# R7FA6M5BH register map
Vendor: Renesas Electronics Corporation; Series: RA6; File version: 1.20.01
CPU: CM33 r0p4, little endian, MPU, FPU, VTOR, 4 interrupt priority bits, 96 interrupts
Registers are 32-bit, read-write, reset 0x0 unless marked. A register's access mark holds for its fields unless they carry their own. Offsets are from the block's base; [hi:lo] are bit positions; {n}, {i} and the like mark numbered series; 'fields as' and 'values as' point back to an identical list; <NAME> marks a mode.

## SYSC — System Control
Base 0x4001E000
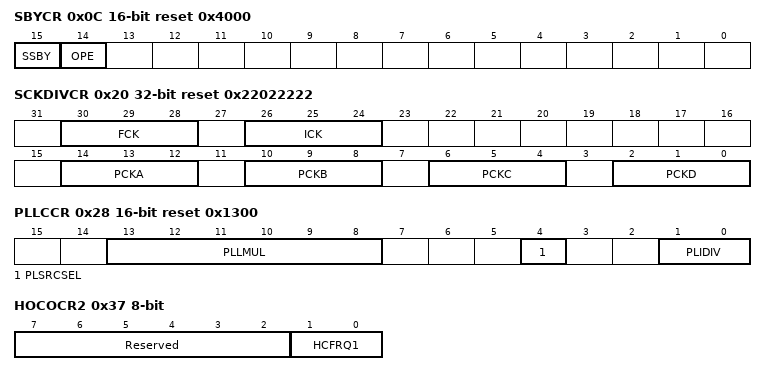
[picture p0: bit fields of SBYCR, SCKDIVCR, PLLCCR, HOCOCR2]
0x0C SBYCR 16-bit reset 0x4000 — Standby Control Register
  [15] SSBY — Software Standby Mode Select
    0=Sleep mode; 1=Software Standby mode
  [14] OPE — Output Port Enable
    0=In Software Standby mode or Deep Software Standby mode, set the address bus and other bus control signal to the high-impedance state. In snooze mode, the status of the address bus and bus control signals are same as before entering Software Standby mode.; 1=In Software Standby mode or Deep Software Standby mode, address bus and other bus control signal retain the output state
0x20 SCKDIVCR reset 0x22022222 — System Clock Division Control Register
  [all] fields
    0=x 1/1; 1=x 1/2; 2=x 1/4; 3=x 1/8; 4=x 1/16; 5=x 1/32; 6=x 1/64; other=Others (Setting prohibited.)
  [30:28] FCK — FlashIF Clock (FCLK) Select
  [26:24] ICK — System Clock (ICLK) Select
  [14:12] PCKA — Peripheral Module Clock A (PCLKA) Select
  [10:8] PCKB — Peripheral Module Clock B (PCLKB) Select
  [6:4] PCKC — Peripheral Module Clock C (PCLKC) Select
  [2:0] PCKD — Peripheral Module Clock D (PCLKD) Select
0x26 SCKSCR 8-bit reset 0x1 — System Clock Source Control Register
  [2:0] CKSEL — Clock Source Select
    0=HOCO; 1=MOCO; 2=LOCO; 3=Main clock oscillator (MOSC); 4=Sub-clock oscillator (SOSC); 5=PLL; 6=Setting prohibited; 7=Setting prohibited
0x28 PLLCCR 16-bit reset 0x1300 — PLL Clock Control Register
  [13:8] PLLMUL range 0x13..0x3B — PLL Frequency Multiplication Factor Select
  [4] PLSRCSEL — PLL Clock Source Select
    0=Main clock oscillator; 1=HOCO
  [1:0] PLIDIV — PLL Input Frequency Division Ratio Select
    0=/1; 1=/2; 2=/3; other=Others (Setting prohibited.)
0x2A PLLCR 8-bit reset 0x1 — PLL Control Register
  [0] PLLSTP — PLL Stop Control
    0=PLL is operating; 1=PLL is stopped
0x30 BCKCR 8-bit — External Bus Clock Control Register
  [0] BCLKDIV — BCLK Pin Output Select
    0=BCLK; 1=BCLK ∕ 2
0x32 MOSCCR 8-bit reset 0x1 — Main Clock Oscillator Control Register
  [0] MOSTP — Main Clock Oscillator Stop
    0=Operate the main clock oscillator; 1=Stop the main clock oscillator
0x36 HOCOCR 8-bit (reset mask 0xFE) — High-Speed On-Chip Oscillator Control Register
  [0] HCSTP — HOCO Stop
    0=Operate the HOCO clock; 1=Stop the HOCO clock
0x37 HOCOCR2 8-bit (reset mask 0xFC) — High-Speed On-Chip Oscillator Control Register 2
  [7:2] Reserved — These bits are read as 000000. The write value should be 000000.
  [1:0] HCFRQ1 — HOCO Frequency Setting 0
    0=16 MHz; 1=18 MHz; 2=20 MHz; other=others (Setting prohibited)
0x38 MOCOCR 8-bit — Middle-Speed On-Chip Oscillator Control Register
  [0] MCSTP — MOCO Stop
    0=MOCO clock is operating; 1=MOCO clock is stopped
0x39 FLLCR1 8-bit — FLL Control Register1
  [0] FLLEN — FLL Enable
    0=FLL function is disabled; 1=FLL function is enabled
0x3A FLLCR2 16-bit — FLL Control Register2
  [10:0] FLLCNTL — FLL Multiplication Control
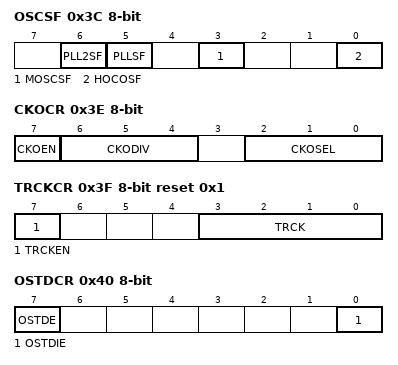
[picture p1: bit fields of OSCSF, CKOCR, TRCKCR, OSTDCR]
0x3C OSCSF 8-bit ro (reset mask 0xFE) — Oscillation Stabilization Flag Register
  [6] PLL2SF — PLL2 Clock Oscillation Stabilization Flag
    0=The PLL2 clock is stopped, or oscillation of the PLL2 clock is not stable yet; 1=The PLL2 clock is stable
  [5] PLLSF — PLL Clock Oscillation Stabilization Flag
    0=The PLL clock is stopped, or oscillation of the PLL clock is not stable yet; 1=The PLL clock is stable, so is available for use as the system clock
  [3] MOSCSF — Main Clock Oscillation Stabilization Flag
    0=The main clock oscillator is stopped (MOSTP = 1) or is not yet stable; 1=The main clock oscillator is stable, so is available for use as the system clock
  [0] HOCOSF — HOCO Clock Oscillation Stabilization Flag
    0=The HOCO clock is stopped or is not yet stable; 1=The HOCO clock is stable, so is available for use as the system clock
0x3E CKOCR 8-bit — Clock Out Control Register
  [7] CKOEN — Clock Out Enable
    0=Disable clock out; 1=Enable clock out
  [6:4] CKODIV — Clock Output Frequency Division Ratio
    0=x 1/1; 1=x 1/2; 2=x 1/4; 3=x 1/8; 4=x 1/16; 5=x 1/32; 6=x 1/64; 7=x 1/128
  [2:0] CKOSEL — Clock Out Source Select
    0=HOCO (value after reset); 1=MOCO; 2=LOCO; 3=MOSC; 4=SOSC; 5=Setting prohibited; other=Others (Setting prohibited)
0x3F TRCKCR 8-bit reset 0x1 — Trace Clock Control Register
  [7] TRCKEN — Trace Clock operating Enable
    0=Stop; 1=Operation enable
  [3:0] TRCK — Trace Clock operating frequency select
    0=/1; 1=/2 (value after reset); 2=/4; other=Others (Setting prohibited)
0x40 OSTDCR 8-bit — Oscillation Stop Detection Control Register
  [7] OSTDE — Oscillation Stop Detection Function Enable
    0=Disable oscillation stop detection function; 1=Enable oscillation stop detection function
  [0] OSTDIE — Oscillation Stop Detection Interrupt Enable
    0=Disable oscillation stop detection interrupt (do not notify the POEG); 1=Enable oscillation stop detection interrupt (notify the POEG)
0x41 OSTDSR 8-bit — Oscillation Stop Detection Status Register
  [0] OSTDF — Oscillation Stop Detection Flag
    0=Main clock oscillation stop not detected; 1=Main clock oscillation stop detected
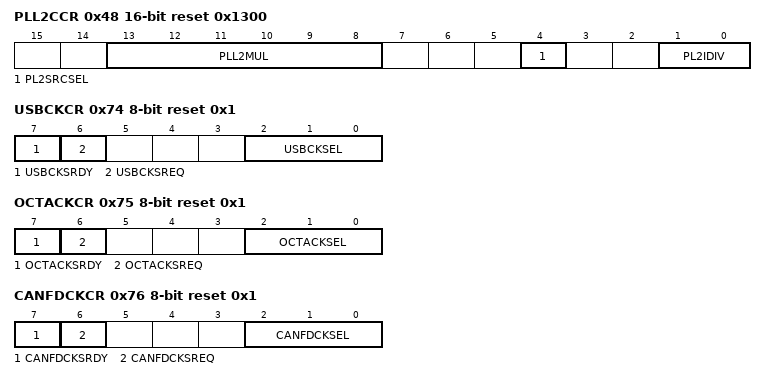
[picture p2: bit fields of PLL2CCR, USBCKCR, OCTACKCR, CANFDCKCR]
0x48 PLL2CCR 16-bit reset 0x1300 — PLL2 Clock Control Register
  [13:8] PLL2MUL — PLL2 Frequency Multiplication Factor Select
  [4] PL2SRCSEL — PLL2 Clock Source Select
    0=Main clock oscillator; 1=HOCO
  [1:0] PL2IDIV — PLL2 Input Frequency Division Ratio Select
    0=∕ 1 (value after reset); 1=∕ 2; 2=∕ 3; other=Others (Setting prohibited.)
0x4A PLL2CR 8-bit reset 0x1 — PLL2 Control Register
  [0] PLL2STP — PLL2 Stop Control
    0=PLL2 is operating; 1=PLL2 is stopped
0x52 EBCKOCR 8-bit — External Bus Clock Output Control Register
  [0] EBCKOEN — EBCLK Pin Output Control
    0=EBCLK pin output is disabled (fixed high); 1=EBCLK pin output is enabled
0x61 MOCOUTCR 8-bit — MOCO User Trimming Control Register
  [7:0] MOCOUTRM — MOCO User Trimming
0x62 HOCOUTCR 8-bit — HOCO User Trimming Control Register
  [7:0] HOCOUTRM — HOCO User Trimming
0x6C USBCKDIVCR 8-bit — USB Clock Division Control Register
  [2:0] USBCKDIV — USB Clock (USBCLK) Division Select
    2=∕ 4; 5=∕ 3; 6=∕ 5; other=Others (Setting prohibited.)
0x6D OCTACKDIVCR 8-bit — Octal-SPI Clock Division Control Register
  [2:0] OCTACKDIV — Octal-SPI Clock (OCTACLK) Division Select
    0=∕ 1 (value after reset); 1=∕ 2; 2=∕ 4; 3=∕ 6; 4=∕ 8; other=Others (Setting prohibited.)
0x6E CANFDCKDIVCR 8-bit — CANFD Clock Division Control Register
  [2:0] CANFDCKDIV — CANFD clock (CANFDCLK) Division Select
    0=/1 (value after reset) /2 /4 /6 /3 /5
0x6F USB60CKDIVCR 8-bit — USB60 Clock Division Control Register
  [2:0] USB60CKDIV — USB clock (USB60CLK) Division Select
    0=/1 (value after reset); 1=/2; 2=/4; 3=/6; 4=/8; 5=/3; 6=/5; other=Others (Setting prohibited)
0x70 CECCKDIVCR 8-bit reset 0x1 — CEC Clock Division Control Register
  [2:0] CECCKDIV — CEC clock (CECCLK) Division Select
    values as USB60CKDIVCR.USB60CKDIV
0x74 USBCKCR 8-bit reset 0x1 — USB Clock Control Register
  [7] USBCKSRDY ro — USB Clock (USBCLK) Switching Ready state flag
    0=Impossible to Switch; 1=Possible to Switch
  [6] USBCKSREQ — USB Clock (USBCLK) Switching Request
    0=No request; 1=Request switching
  [2:0] USBCKSEL — USB Clock (USBCLK) Source Select
    5=PLL; 6=PLL2; other=Others (Setting prohibited.)
0x75 OCTACKCR 8-bit reset 0x1 — Octal-SPI Clock Control Register
  [7] OCTACKSRDY ro — Octal-SPI Clock (OCTACLK) Switching Ready state flag
    0=Switching not possible; 1=Switching possible
  [6] OCTACKSREQ — Octal-SPI Clock (OCTACLK) Switching Request
    0=No request; 1=Request switching
  [2:0] OCTACKSEL — Octal-SPI Clock (OCTACLK) Source Select
    0=HOCO; 1=MOCO (value after reset); 2=LOCO; 3=Main clock oscillator; 4=Sub-clock oscillator; 5=PLL; 6=PLL2; other=Others (Setting prohibited.)
0x76 CANFDCKCR 8-bit reset 0x1 — CANFD Clock Control Register
  [7] CANFDCKSRDY ro — CANFD clock (CANFDCLK) Switching Ready state flag
    0=Impossible to Switch; 1=Possible to Switch
  [6] CANFDCKSREQ — CANFD clock (CANFDCLK) Switching Request
    0=No request; 1=Request switching
  [2:0] CANFDCKSEL — CANFD clock (CANFDCLK) Source Select
    5=PLL; 6=PLL2; other=Others (Setting prohibited)
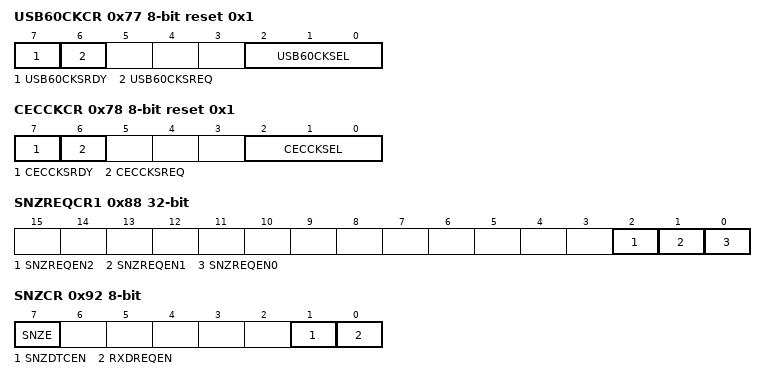
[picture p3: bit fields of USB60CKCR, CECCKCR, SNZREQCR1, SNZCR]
0x77 USB60CKCR 8-bit reset 0x1 — USB60 Clock Control Register
  [7] USB60CKSRDY ro — USB clock (USB60CLK) Switching Ready state flag
    0=Impossible to Switch; 1=Possible to Switch
  [6] USB60CKSREQ — USB clock (USB60CLK) Switching Request
    0=No request; 1=Request switching
  [2:0] USB60CKSEL — USB clock (USB60CLK) Source Select
    5=PLL; 6=PLL2; other=Others (Setting prohibited)
0x78 CECCKCR 8-bit reset 0x1 — CEC Clock Control Register
  [7] CECCKSRDY ro — CEC clock (CECCLK) Switching Ready state flag
    0=Impossible to Switch; 1=Possible to Switch
  [6] CECCKSREQ — CEC clock (CECCLK) Switching Request
    0=No request; 1=Request switching
  [2:0] CECCKSEL — CEC clock (CECCLK) Source Select
    3=Main clock oscillator; 4=Sub-clock oscillator; other=Others (Setting prohibited)
0x88 SNZREQCR1 — Snooze Request Control Register 1
  [all] fields
    0=Disable the snooze request; 1=Enable the snooze request
  [2] SNZREQEN2 — Enable AGT3 compare match B snooze request
  [1] SNZREQEN1 — Enable AGT3 compare match A snooze request
  [0] SNZREQEN0 — Enable AGT3 underflow snooze request
0x92 SNZCR 8-bit — Snooze Control Register
  [7] SNZE — Snooze mode Enable
    0=Disable Snooze mode; 1=Enable Snooze mode
  [1] SNZDTCEN — DTC Enable in Snooze mode
    0=Disable DTC operation; 1=Enable DTC operation
  [0] RXDREQEN — RXD0 Snooze Request Enable
    0=Ignore RXD0 falling edge in Software Standby mode; 1=Detect RXD0 falling edge in Software Standby mode
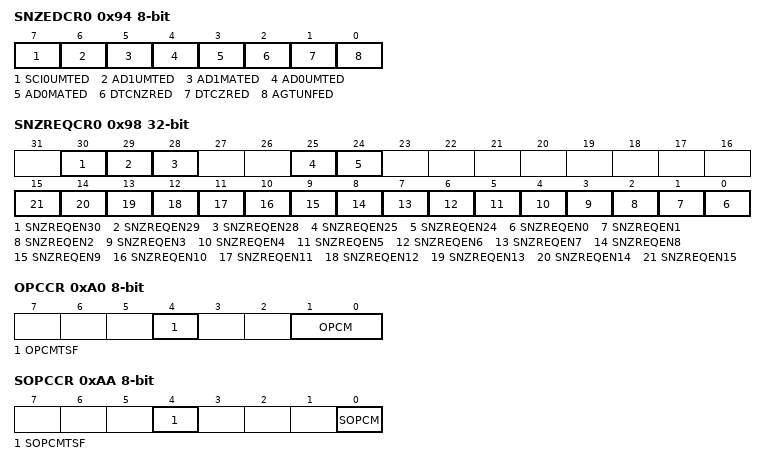
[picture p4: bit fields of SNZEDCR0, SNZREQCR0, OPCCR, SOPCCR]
0x94 SNZEDCR0 8-bit — Snooze End Control Register 0
  [all] fields
    0=Disable the snooze end request; 1=Enable the snooze end request
  [7] SCI0UMTED — SCI0 Address Mismatch Snooze End Enable
  [6] AD1UMTED — ADC121 Compare Mismatch Snooze End Enable
  [5] AD1MATED — ADC121 Compare Match Snooze End Enable
  [4] AD0UMTED — ADC120 Compare Mismatch Snooze End Enable
  [3] AD0MATED — ADC120 Compare Match Snooze End Enable
  [2] DTCNZRED — Not Last DTC Transmission Completion Snooze End Enable
  [1] DTCZRED — Last DTC Transmission Completion Snooze End Enable
  [0] AGTUNFED — AGT1 Underflow Snooze End Enable
0x95 SNZEDCR1 8-bit — Snooze End Control Register 1
  [0] AGT3UNFED — AGT3 underflow Snooze End Enable
    0=Disable the Snooze End request; 1=Enable the Snooze End request
0x98 SNZREQCR0 — Snooze Request Control Register 0
  [all] fields
    0=Disable the snooze request; 1=Enable the snooze request
  [30] SNZREQEN30 — Enable AGT1 compare match B snooze request
  [29] SNZREQEN29 — Enable AGT1 compare match A snooze request
  [28] SNZREQEN28 — Enable AGT1 underflow snooze request
  [25] SNZREQEN25 — Enable RTC period snooze request
  [24] SNZREQEN24 — Enable RTC alarm snooze request
  [n] SNZREQEN{n} (n=0..15) — Enable IRQ{n} pin snooze request
0xA0 OPCCR 8-bit — Operating Power Control Register
  [4] OPCMTSF ro — Operating Power Control Mode Transition Status Flag
    0=Transition completed; 1=During transition
  [1:0] OPCM — Operating Power Control Mode Select
    0=High-speed mode; 1=Setting prohibited; 2=Setting prohibited; 3=Low-speed mode
0xA2 MOSCWTCR 8-bit reset 0x5 — Main Clock Oscillator Wait Control Register
  [3:0] MSTS — Main Clock Oscillator Wait Time Setting
    0=Wait time = 3 cycles (11.4 us); 1=Wait time = 35 cycles (133.5 us); 2=Wait time = 67 cycles (255.6 us); 3=Wait time = 131 cycles (499.7 us); 4=Wait time = 259 cycles (988.0 us); 5=Wait time = 547 cycles (2086.6 us); 6=Wait time = 1059 cycles (4039.8 us); 7=Wait time = 2147 cycles (8190.2 us); 8=Wait time = 4291 cycles (16368.9 us); 9=Wait time = 8163 cycles (31139.4 us); other=Others (Setting prohibited)
0xAA SOPCCR 8-bit — Sub Operating Power Control Register
  [4] SOPCMTSF ro — Operating Power Control Mode Transition Status Flag
    0=Transition completed; 1=During transition
  [0] SOPCM — Sub Operating Power Control Mode Select
    0=Other than Subosc-speed mode; 1=Subosc-speed mode
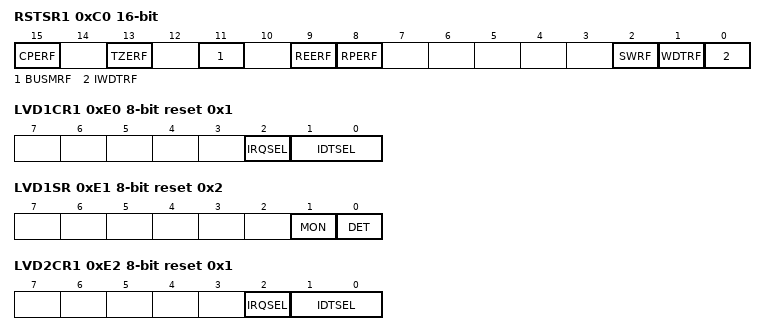
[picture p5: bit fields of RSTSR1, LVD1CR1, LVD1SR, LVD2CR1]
0xC0 RSTSR1 16-bit (reset mask 0x54F8) — Reset Status Register 1
  [15] CPERF — Cache Parity Error Reset Detect Flag
    0=Cache Parity error reset not detected; 1=Cache Parity error reset detected
  [13] TZERF — TrustZone Error Reset Detect Flag
    0=TrustZone error reset not detected; 1=TrustZone error reset detected
  [11] BUSMRF — Bus Master MPU Error Reset Detect Flag
    0=Bus master MPU error reset not detected; 1=Bus master MPU error reset detected
  [9] REERF — SRAM ECC Error Reset Detect Flag
    0=SRAM ECC error reset not detected; 1=SRAM ECC error reset detected
  [8] RPERF — SRAM Parity Error Reset Detect Flag
    0=SRAM parity error reset not detected; 1=SRAM parity error reset detected
  [2] SWRF — Software Reset Detect Flag
    0=Software reset not detected; 1=Software reset detected
  [1] WDTRF — Watchdog Timer Reset Detect Flag
    0=Watchdog timer reset not detected; 1=Watchdog timer reset detected
  [0] IWDTRF — Independent Watchdog Timer Reset Detect Flag
    0=Independent watchdog timer reset not detected; 1=Independent watchdog timer reset detected
0xE0 LVD1CR1 8-bit reset 0x1 — Voltage Monitor 1 Circuit Control Register
  [2] IRQSEL — Voltage Monitor 1 Interrupt Type Select
    0=Non-maskable interrupt; 1=Maskable interrupt
  [1:0] IDTSEL — Voltage Monitor 1 Interrupt Generation Condition Select
    0=When VCC >= Vdet1 (rise) is detected; 1=When VCC < Vdet1 (fall) is detected; 2=When fall and rise are detected; 3=Settings prohibited
0xE1 LVD1SR 8-bit reset 0x2 — Voltage Monitor 1 Circuit Status Register
  [1] MON ro — Voltage Monitor 1 Signal Monitor Flag
    0=VCC < Vdet1; 1=VCC >= Vdet1 or MON is disabled
  [0] DET — Voltage Monitor 1 Voltage Variation Detection Flag
    0=Not detected; 1=Vdet1 crossing is detected
0xE2 LVD2CR1 8-bit reset 0x1 — Voltage Monitor 2 Circuit Control Register 1
  [2] IRQSEL — Voltage Monitor 2 Interrupt Type Select
    0=Non-maskable interrupt; 1=Maskable interrupt
  [1:0] IDTSEL — Voltage Monitor 2 Interrupt Generation Condition Select
    0=When VCC>= Vdet2 (rise) is detected; 1=When VCC < Vdet2 (fall) is detected; 2=When fall and rise are detected; 3=Settings prohibited
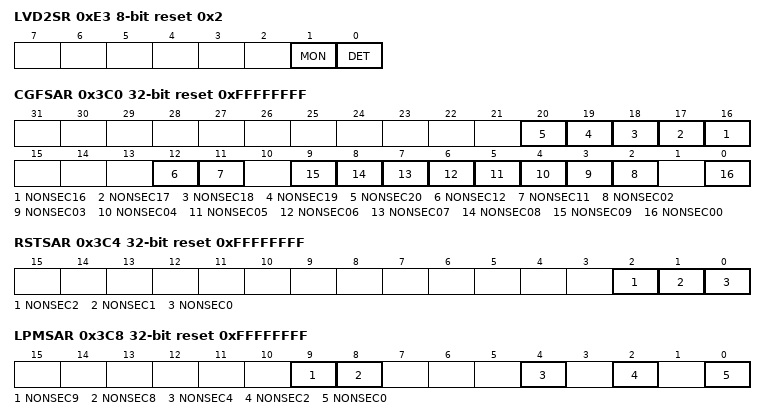
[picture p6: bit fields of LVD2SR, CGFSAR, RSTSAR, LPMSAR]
0xE3 LVD2SR 8-bit reset 0x2 — Voltage Monitor 2 Circuit Status Register
  [1] MON ro — Voltage Monitor 2 Signal Monitor Flag
    0=VCC < Vdet2; 1=VCC>= Vdet2 or MON is disabled
  [0] DET — Voltage Monitor 2 Voltage Variation Detection Flag
    0=Not detected; 1=Vdet2 crossing is detected
0x3C0 CGFSAR reset 0xFFFFFFFF — Clock Generation Function Security Attribute Register
  [all] fields
    0=Secure; 1=Non Secure
  [n] NONSEC{n} (n=16..20) — Non Secure Attribute bit {n}
  [12] NONSEC12 — Non Secure Attribute bit 12
  [11] NONSEC11 — Non Secure Attribute bit 11
  [n] NONSEC{n:02} (n=2..9) — Non Secure Attribute bit {n:02}
  [0] NONSEC00 — Non Secure Attribute bit 00
0x3C4 RSTSAR reset 0xFFFFFFFF — Reset Security Attribution Register
  [all] fields
    0=Secure; 1=Non Secure
  [2] NONSEC2 — Non Secure Attribute bit 2
  [1] NONSEC1 — Non Secure Attribute bit 1
  [0] NONSEC0 — Non Secure Attribute bit 0
0x3C8 LPMSAR reset 0xFFFFFFFF — Low Power Mode Security Attribution Register
  [all] fields
    0=Secure; 1=Non Secure
  [9] NONSEC9 — Non Secure Attribute bit 9
  [8] NONSEC8 — Non Secure Attribute bit 8
  [4] NONSEC4 — Non Secure Attribute bit 4
  [2] NONSEC2 — Non Secure Attribute bit 2
  [0] NONSEC0 — Non Secure Attribute bit 0
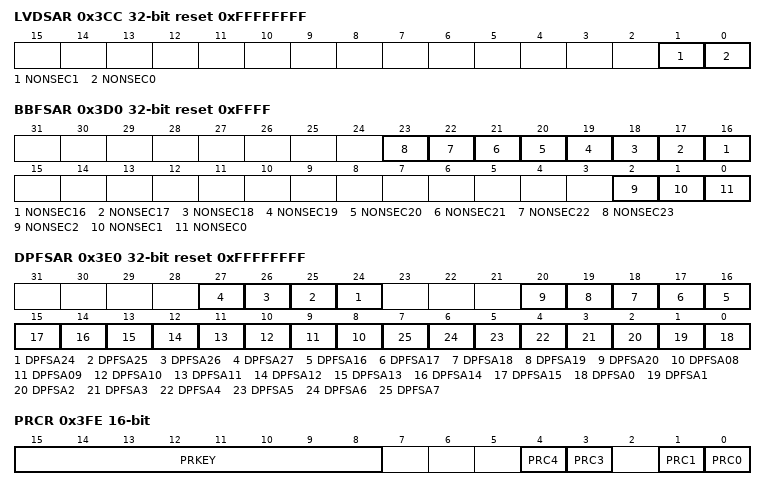
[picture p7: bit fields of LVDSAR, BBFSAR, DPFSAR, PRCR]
0x3CC LVDSAR reset 0xFFFFFFFF — Low Voltage Detection Security Attribution Register
  [1] NONSEC1 — Non Secure Attribute bit 1
    0=Secure; 1=Non Secure
  [0] NONSEC0 — Non Secure Attribute bit 0
    0=Secure; 1=Non Secure
0x3D0 BBFSAR reset 0xFFFF — Battery Backup Function Security Attribute Register
  [all] fields
    0=Secure; 1=Non Secure
  [n] NONSEC{n} (n=16..23) — Non Secure Attribute bit {n}
  [2] NONSEC2 — Non Secure Attribute bit 2
  [1] NONSEC1 — Non Secure Attribute bit 1
  [0] NONSEC0 — Non Secure Attribute bit 0
0x3E0 DPFSAR reset 0xFFFFFFFF — Deep Software Standby Interrupt Factor Security Attribution Register
  [all] fields
    0=Secure; 1=Non Secure
  [n] DPFSA{n} (n=24..27) — Deep Software Standby Interrupt Factor Security Attribute bit {n}
  [n] DPFSA{n} (n=16..20) — Deep Software Standby Interrupt Factor Security Attribute bit {n}
  [n] DPFSA{n:02} (n=8..15) — Deep Software Standby Interrupt Factor Security Attribute bit n (n = 8 to 15)
  [n] DPFSA{n} (n=0..7) — Deep Software Standby Interrupt Factor Security Attribute bit n (n = 0 to 7)
0x3FE PRCR 16-bit — Protect Register
  [15:8] PRKEY wo — PRC Key Code
  [4] PRC4
    0=Disable writes; 1=Enable writes
  [3] PRC3 — Enable writing to the registers related to the LVD
    0=Disable writes; 1=Enable writes
  [1] PRC1 — Enable writing to the registers related to the low power modes, and the battery backup function
    0=Disable writes; 1=Enable writes
  [0] PRC0 — Enable writing to the registers related to the clock generation circuit
    0=Disable writes; 1=Enable writes
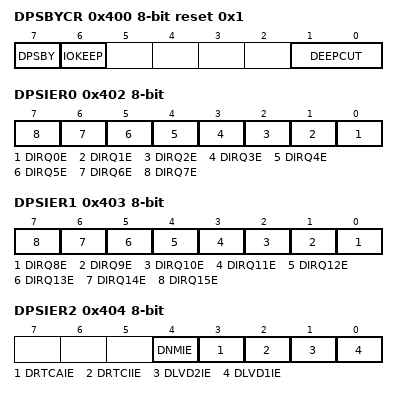
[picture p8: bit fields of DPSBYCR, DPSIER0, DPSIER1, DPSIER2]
0x400 DPSBYCR 8-bit reset 0x1 — Deep Software Standby Control Register
  [7] DPSBY — Deep Software Standby
    0=Sleep mode (SBYCR.SSBY=0) / Software Standby mode (SBYCR.SSBY=1); 1=Sleep mode (SBYCR.SSBY=0) / Deep Software Standby mode (SBYCR.SSBY=1)
  [6] IOKEEP — I/O Port Rentention
    0=When the Deep Software Standby mode is canceled, the I/O ports are in the reset state; 1=When the Deep Software Standby mode is canceled, the I/O ports are in the same state as in the Deep Software Standby mode
  [1:0] DEEPCUT — Power-Supply Control
    0=Power to the standby RAM, Low-speed on-chip oscillator, AGTn (n = 0 to 3), and USBFS/USBHS resume detecting unit is supplied in Deep Software Standby mode; 1=Power to the standby RAM, Low-speed on-chip oscillator, AGT, and USBFS/USBHS resume detecting unit is not supplied in Deep Software Standby mode; 2=Setting prohibited; 3=Power to the standby RAM, Low-speed on-chip oscillator, AGT, and USBFS/USBHS resume detecting unit is not supplied in Deep Software Standby mode. In addition, LVD is disabled and the low power function in a power-on reset circuit is enabled.
0x401 DPSWCR 8-bit reset 0x19 — Deep Software Standby Wait Control Register
  [5:0] WTSTS — Deep Software Wait Standby Time Setting Bit
    14=Wait cycle for fast recovery; 25=Wait cycle for slow recovery; other=Others (Setting prohibited)
0x402 DPSIER0 8-bit — Deep Software Standby Interrupt Enable Register 0
  [all] fields
    0=Cancelling Deep Software Standby mode is disabled; 1=Cancelling Deep Software Standby mode is enabled
  [n] DIRQ{n}E (n=0..7) — IRQ{n}-DS Pin Enable
0x403 DPSIER1 8-bit — Deep Software Standby Interrupt Enable Register 1
  [all] fields
    values as the fields of DPSIER0
  [n-8] DIRQ{n}E (n=8..15) — IRQ{n}-DS Pin Enable
0x404 DPSIER2 8-bit — Deep Software Standby Interrupt Enable Register 2
  [all] fields
    values as the fields of DPSIER0
  [4] DNMIE — NMI Pin Enable
  [3] DRTCAIE — RTC Alarm interrupt Deep Software Standby Cancel Signal Enable
  [2] DRTCIIE — RTC Interval interrupt Deep Software Standby Cancel Signal Enable
  [1] DLVD2IE — LVD2 Deep Software Standby Cancel Signal Enable
  [0] DLVD1IE — LVD1 Deep Software Standby Cancel Signal Enable
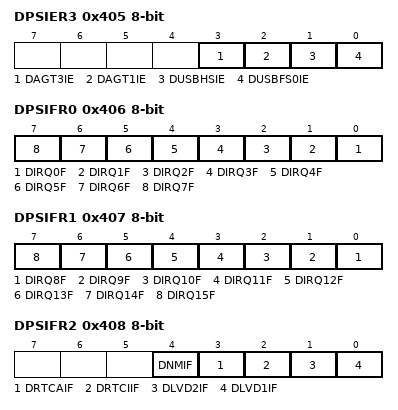
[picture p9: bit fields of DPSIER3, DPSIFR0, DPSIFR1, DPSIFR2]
0x405 DPSIER3 8-bit — Deep Software Standby Interrupt Enable Register 3
  [all] fields
    values as the fields of DPSIER0
  [3] DAGT3IE — AGT3 Underflow Deep Software Standby Cancel Signal Enable
  [2] DAGT1IE — AGT1 Underflow Deep Software Standby Cancel Signal Enable
  [1] DUSBHSIE — USBHS Suspend/Resume Deep Software Standby Cancel Signal Enable
  [0] DUSBFS0IE — USBFS0 Suspend/Resume Deep Software Standby Cancel Signal Enable
0x406 DPSIFR0 8-bit — Deep Software Standby Interrupt Flag Register 0
  [all] fields
    0=The cancel request is not generated; 1=The cancel request is generated
  [n] DIRQ{n}F (n=0..7) — IRQ{n}-DS Pin Deep Software Standby Cancel Flag
0x407 DPSIFR1 8-bit — Deep Software Standby Interrupt Flag Register 1
  [all] fields
    values as the fields of DPSIFR0
  [n-8] DIRQ{n}F (n=8..15) — IRQ{n}-DS Pin Deep Software Standby Cancel Flag
0x408 DPSIFR2 8-bit — Deep Software Standby Interrupt Flag Register 2
  [all] fields
    values as the fields of DPSIFR0
  [4] DNMIF — NMI Pin Deep Software Standby Cancel Flag
  [3] DRTCAIF — RTC Alarm Interrupt Deep Software Standby Cancel Flag
  [2] DRTCIIF — RTC Interval Interrupt Deep Software Standby Cancel Flag
  [1] DLVD2IF — LVD2 Deep Software Standby Cancel Flag
  [0] DLVD1IF — LVD1 Deep Software Standby Cancel Flag
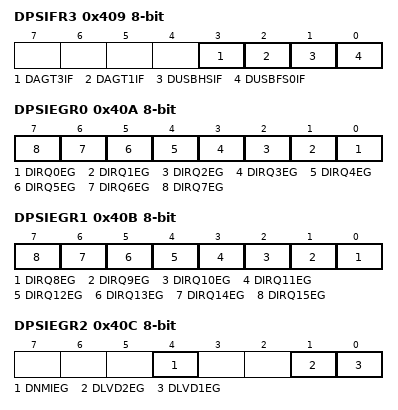
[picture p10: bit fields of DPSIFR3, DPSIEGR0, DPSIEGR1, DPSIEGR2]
0x409 DPSIFR3 8-bit — Deep Software Standby Interrupt Flag Register 3
  [all] fields
    values as the fields of DPSIFR0
  [3] DAGT3IF — AGT3 Underflow Deep Software Standby Cancel Flag
  [2] DAGT1IF — AGT1 Underflow Deep Software Standby Cancel Flag
  [1] DUSBHSIF — USBHS Suspend/Resume Deep Software Standby Cancel Flag
  [0] DUSBFS0IF — USBFS0 Suspend/Resume Deep Software Standby Cancel Flag
0x40A DPSIEGR0 8-bit — Deep Software Standby Interrupt Edge Register 0
  [all] fields
    0=A cancel request is generated at a falling edge; 1=A cancel request is generated at a rising edge
  [n] DIRQ{n}EG (n=0..7) — IRQ{n}-DS Pin Edge Select
0x40B DPSIEGR1 8-bit — Deep Software Standby Interrupt Edge Register 1
  [all] fields
    values as the fields of DPSIEGR0
  [n-8] DIRQ{n}EG (n=8..15) — IRQ{n}-DS Pin Edge Select
0x40C DPSIEGR2 8-bit — Deep Software Standby Interrupt Edge Register 2
  [4] DNMIEG — NMI Pin Edge Select
    values as the fields of DPSIEGR0
  [1] DLVD2EG — LVD2 Edge Select
    0=A cancel request is generated when VCC < Vdet2 (fall) is detected; 1=A cancel request is generated when VCC ≥ Vdet2 (rise) is detected
  [0] DLVD1EG — LVD1 Edge Select
    0=A cancel request is generated when VCC < Vdet1 (fall) is detected; 1=A cancel request is generated when VCC ≥ Vdet1 (rise) is detected
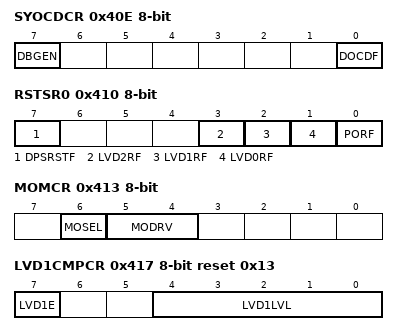
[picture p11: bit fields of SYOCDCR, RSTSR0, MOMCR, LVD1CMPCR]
0x40E SYOCDCR 8-bit (reset mask 0xFE) — System Control OCD Control Register
  [7] DBGEN — Debugger Enable bit
    0=On-chip debugger is disabled; 1=On-chip debugger is enabled
  [0] DOCDF — Deep Software Standby OCD flag
    0=DBIRQ is not generated; 1=DBIRQ is generated
0x410 RSTSR0 8-bit (reset mask 0x70) — Reset Status Register 0
  [7] DPSRSTF — Deep Software Standby Reset Detect Flag
    0=Deep software standby mode cancellation not requested by an interrupt; 1=Deep software standby mode cancellation requested by an interrupt
  [3] LVD2RF — Voltage Monitor 2 Reset Detect Flag
    0=Voltage monitor 2 reset not detected; 1=Voltage monitor 2 reset detected
  [2] LVD1RF — Voltage Monitor 1 Reset Detect Flag
    0=Voltage monitor 1 reset not detected; 1=Voltage monitor 1 reset detected
  [1] LVD0RF — Voltage Monitor 0 Reset Detect Flag
    0=Voltage monitor 0 reset not detected; 1=Voltage monitor 0 reset detected
  [0] PORF — Power-On Reset Detect Flag
    0=Power-on reset not detected; 1=Power-on reset detected
0x411 RSTSR2 8-bit (reset mask 0xFE) — Reset Status Register 2
  [0] CWSF — Cold/Warm Start Determination Flag
    0=Cold start; 1=Warm start
0x413 MOMCR 8-bit — Main Clock Oscillator Mode Oscillation Control Register
  [6] MOSEL — Main Clock Oscillator Switching
    0=Resonator; 1=External clock input
  [5:4] MODRV — Main Clock Oscillator Drive Capability 0 Switching
    0=20 MHz to 24 MHz; 1=16 MHz to 20 MHz; 2=8 MHz to 16 MHz; 3=8 MHz
0x416 FWEPROR 8-bit reset 0x2 — Flash P/E Protect Register
  [1:0] FLWE — Flash Programming and Erasure
    0=Prohibits Program, Block Erase, Multi Block Erase, Blank Check, and Configuration set command processing; 1=Permits Program, Block Erase, Multi Block Erase, Blank Check, and Configuration set command processing; 2=Prohibits Program, Block Erase, Multi Block Erase, Blank Check, and Configuration set command processing; 3=Prohibits Program, Block Erase, Multi Block Erase, Blank Check, and Configuration set command processing
0x417 LVD1CMPCR 8-bit reset 0x13 — Voltage Monitoring 1 Comparator Control Register
  [7] LVD1E — Voltage Detection 1 Enable
    0=Voltage detection 1 circuit disabled; 1=Voltage detection 1 circuit enabled
  [4:0] LVD1LVL — Voltage Detection 1 Level Select (Standard voltage during drop in voltage)
    17=2.99 V (Vdet1_1); 18=2.92 V (Vdet1_2); 19=2.85 V (Vdet1_3); other=Others (Setting prohibited)
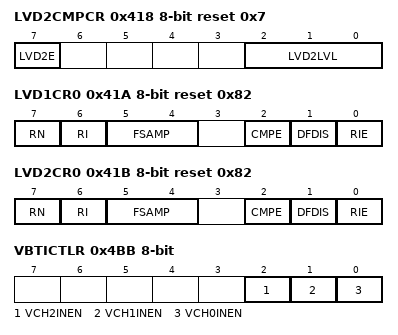
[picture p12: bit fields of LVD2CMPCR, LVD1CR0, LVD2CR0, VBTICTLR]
0x418 LVD2CMPCR 8-bit reset 0x7 — Voltage Monitoring 2 Comparator Control Register
  [7] LVD2E — Voltage Detection 2 Enable
    0=Voltage detection 2 circuit disabled; 1=Voltage detection 2 circuit enabled
  [2:0] LVD2LVL — Voltage Detection 2 Level Select (Standard voltage during drop in voltage)
    5=2.99 V (Vdet2_1); 6=2.92 V (Vdet2_2); 7=2.85 V (Vdet2_3); other=Others (Setting prohibited)
0x41A LVD1CR0 8-bit reset 0x82 — Voltage Monitor 1 Circuit Control Register 0
  [7] RN — Voltage Monitor 1 Reset Negate Select
    0=Negate after a stabilization time (tLVD1) when VCC > Vdet1 is detected; 1=Negate after a stabilization time (tLVD1) on assertion of the LVD1 reset
  [6] RI — Voltage Monitor 1 Circuit Mode Select
    0=Generate voltage monitor 1 interrupt on Vdet1 crossing; 1=Enable voltage monitor 1 reset when the voltage falls to and below Vdet1
  [5:4] FSAMP — Sampling Clock Select
    0=1/2 LOCO frequency; 1=1/4 LOCO frequency; 2=1/8 LOCO frequency; 3=1/16 LOCO frequency
  [2] CMPE — Voltage Monitor 1 Circuit Comparison Result Output Enable
    0=Disable voltage monitor 1 circuit comparison result output; 1=Enable voltage monitor 1 circuit comparison result output
  [1] DFDIS — Voltage monitor 1 Digital Filter Disabled Mode Select
    0=Enable the digital filter; 1=Disable the digital filter
  [0] RIE — Voltage Monitor 1 Interrupt/Reset Enable
    0=Disable; 1=Enable
0x41B LVD2CR0 8-bit reset 0x82 — Voltage Monitor 2 Circuit Control Register 0
  [7] RN — Voltage Monitor 2 Reset Negate Select
    0=Negate after a stabilization time (tLVD2) when VCC > Vdet2 is detected; 1=Negate after a stabilization time (tLVD2) on assertion of the LVD2 reset
  [6] RI — Voltage Monitor 2 Circuit Mode Select
    0=Generate voltage monitor 2 interrupt on Vdet2 crossing; 1=Enable voltage monitor 2 reset when the voltage falls to and below Vdet2
  [5:4] FSAMP — Sampling Clock Select
    values as LVD1CR0.FSAMP
  [2] CMPE — Voltage Monitor 2 Circuit Comparison Result Output Enable
    0=Disable voltage monitor 2 circuit comparison result output; 1=Enable voltage monitor 2 circuit comparison result output
  [1] DFDIS — Voltage monitor 2 Digital Filter Disabled Mode Select
    0=Enable the digital filter; 1=Disable the digital filter
  [0] RIE — Voltage Monitor 2 Interrupt/Reset Enable
    0=Disable; 1=Enable
0x41D VBATTMNSELR 8-bit — Battery Backup Voltage Monitor Function Select Register
  [0] VBATTMNSEL — VBATT Low Voltage Detect Function Select Bit
    0=Disables VBATT low voltage detect function; 1=Enables VBATT low voltage detect function
0x41E VBATTMONR 8-bit ro — Battery Backup Voltage Monitor Register
  [0] VBATTMON — VBATT Voltage Monitor Bit
    0=VBATT ≥ Vbattldet; 1=VBATT < Vbattldet
0x480 SOSCCR 8-bit — Sub-Clock Oscillator Control Register
  [0] SOSTP — Sub Clock Oscillator Stop
    0=Operate the sub-clock oscillator; 1=Stop the sub-clock oscillator
0x481 SOMCR 8-bit — Sub-Clock Oscillator Mode Control Register
  [1] SODRV — Sub-Clock Oscillator Drive Capability Switching
    0=Standard; 1=Low
0x490 LOCOCR 8-bit — Low-Speed On-Chip Oscillator Control Register
  [0] LCSTP — LOCO Stop
    0=Operate the LOCO clock; 1=Stop the LOCO clock
0x492 LOCOUTCR 8-bit — LOCO User Trimming Control Register
  [7:0] LOCOUTRM — LOCO User Trimming
0x4BB VBTICTLR 8-bit (reset mask 0xF8) — VBATT Input Control Register
  [2] VCH2INEN — VBATT CH2 Input Enable
    0=RTCIC2 input disable; 1=RTCIC2 input enable
  [1] VCH1INEN — VBATT CH1 Input Enable
    0=RTCIC1 input disable; 1=RTCIC1 input enable
  [0] VCH0INEN — VBATT CH0 Input Enable
    0=RTCIC0 input disable; 1=RTCIC0 input enable
0x4C0 VBTBER 8-bit reset 0x8 — VBATT Backup Enable Register
  [3] VBAE — VBATT backup register access enable bit
    0=Disable to access VBTBKR; 1=Enable to access VBTBKR
{0x500+i} VBTBKR[{i}] (i=0..127) 8-bit reset not defined — VBATT Backup Register
  [7:0] VBTBKR
